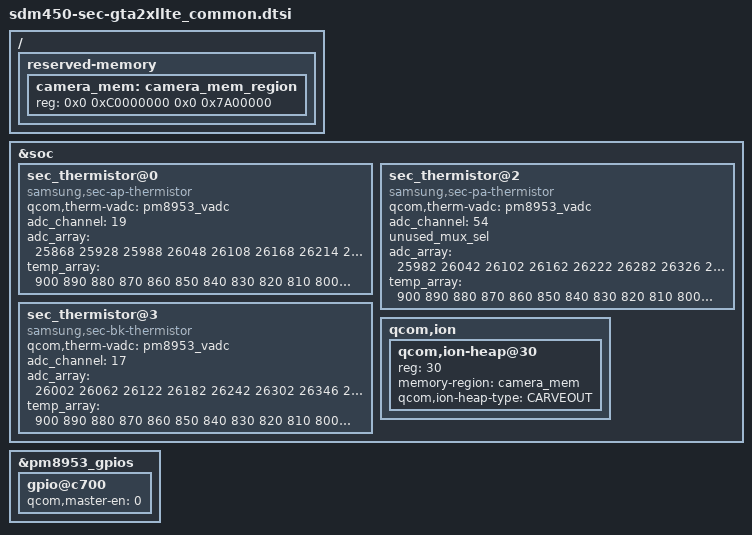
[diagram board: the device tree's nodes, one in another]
/* Copyright (c) 2017, The Linux Foundation. All rights reserved.
 *
 * This program is free software; you can redistribute it and/or modify
 * it under the terms of the GNU General Public License version 2 and
 * only version 2 as published by the Free Software Foundation.
 *
 * This program is distributed in the hope that it will be useful,
 * but WITHOUT ANY WARRANTY; without even the implied warranty of
 * MERCHANTABILITY or FITNESS FOR A PARTICULAR PURPOSE.  See the
 * GNU General Public License for more details.
 */

#include "../qcom/sdm450.dtsi"
#include "sdm450-sec-common.dtsi"
#include "sdm450-s2mu004.dtsi"
#include "sdm450-s2mm005.dtsi"
#include "sdm450-sec-gta2xllte_audio.dtsi"
#include "sdm450-sec-gta2xllte-input-common.dtsi"


/ {
	reserved-memory {
		camera_mem: camera_mem_region {
			reg = <0x0 0xC0000000 0x0 0x7A00000>;
		};
	};
};

&soc {
	/* Thermistor table */
	sec_thermistor@0 {
		compatible = "samsung,sec-ap-thermistor";
		qcom,therm-vadc = <&pm8953_vadc>;
		status = "okay";
		adc_channel = <19>;
					
		adc_array = <25868 25928 25988 26048 26108 26168 26214 26261 26307 26354
					26400 26447 26494 26540 26587 26634 26699 26765 26830 26896
					26961 27020 27080 27139 27199 27258 27352 27446 27539 27633
					27727 27842 27958 28073 28189 28304 28430 28556 28682 28808
					28934 29141 29349 29556 29764 29971 30163 30356 30548 30741
					30933 31122 31311 31499 31688 31877 32012 32147 32281 32416
					32551 32706 32861 33015 33170 33325 33593 33861 34129 34397
					34665 34889 35114 35338 35563 35787 35998 36209 36420 36631
					36842 37044 37245 37447 37648 37850 37994 38138 38283 38427
					38571 38743 38914 39086 39257 39429 39569 39709 39849 39989
					40129 40249 40370 40490 40611 40731 40826 40921 41015 41110
					41205>;

		temp_array = <900 890 880 870 860 850 840 830 820 810
			800 790 780 770 760 750 740 730 720 710
			700 690 680 670 660 650 640 630 620 610
			600 590 580 570 560 550 540 530 520 510
			500 490 480 470 460 450 440 430 420 410
			400 390 380 370 360 350 340 330 320 310
			300 290 280 270 260 250 240 230 220 210
			200 190 180 170 160 150 140 130 120 110
			100 90 80 70 60 50 40 30 20 10
			0 (-10) (-20) (-30) (-40) (-50) (-60) (-70) (-80) (-90)
			(-100) (-110) (-120) (-130) (-140) (-150) (-160) (-170) (-180) (-190)
			(-200)>;
	};
	
	/* PA Thermistor table */
	sec_thermistor@2 {
		compatible = "samsung,sec-pa-thermistor";
		qcom,therm-vadc = <&pm8953_vadc>;
		status = "okay";
		adc_channel = <54>;
		unused_mux_sel;

		adc_array = <25982 26042 26102 26162 26222 26282 26326 26369 26413 26456
					26500 26552 26604 26655 26707 26759 26827 26896 26964 27033
					27101 27162 27223 27284 27345 27406 27502 27599 27695 27792
					27888 28004 28120 28235 28351 28467 28598 28729 28860 28991
					29122 29292 29463 29633 29804 29974 30147 30321 30494 30668
					30841 31031 31222 31412 31603 31793 31991 32190 32388 32587
					32785 32985 33185 33384 33584 33784 34018 34252 34487 34721
					34955 35175 35395 35615 35835 36055 36271 36487 36704 36920
					37136 37338 37540 37742 37944 38146 38308 38470 38631 38793
					38955 39125 39295 39465 39635 39805 39945 40085 40226 40366
					40506 40626 40746 40866 40986 41106 41202 41297 41393 41488
					41584>;

		temp_array = <900 890 880 870 860 850 840 830 820 810
			800 790 780 770 760 750 740 730 720 710
			700 690 680 670 660 650 640 630 620 610
			600 590 580 570 560 550 540 530 520 510
			500 490 480 470 460 450 440 430 420 410
			400 390 380 370 360 350 340 330 320 310
			300 290 280 270 260 250 240 230 220 210
			200 190 180 170 160 150 140 130 120 110
			100 90 80 70 60 50 40 30 20 10
			0 (-10) (-20) (-30) (-40) (-50) (-60) (-70) (-80) (-90)
			(-100) (-110) (-120) (-130) (-140) (-150) (-160) (-170) (-180) (-190)
			(-200)>;
	};
	
	/* BLANKET Thermistor table */
	sec_thermistor@3 {
		compatible = "samsung,sec-bk-thermistor";
		qcom,therm-vadc = <&pm8953_vadc>;
		status = "okay";
		adc_channel = <17>;

		adc_array = <26002 26062 26122 26182 26242 26302 26346 26389 26433 26476
					26520 26571 26622 26673 26724 26775 26844 26913 26982 27051
					27120 27182 27244 27305 27367 27429 27525 27621 27718 27814
					27910 28024 28139 28253 28368 28482 28613 28743 28874 29004
					29135 29307 29479 29651 29823 29995 30167 30339 30511 30683
					30855 31045 31234 31424 31613 31803 32002 32201 32400 32599
					32798 33003 33208 33414 33619 33824 34049 34275 34500 34726
					34951 35168 35385 35601 35818 36035 36248 36462 36675 36889
					37102 37299 37496 37694 37891 38088 38246 38404 38563 38721
					38879 39042 39205 39369 39532 39695 39830 39965 40099 40234
					40369 40483 40597 40710 40824 40938 41028 41118 41207 41297
					41387>;

		temp_array = <900 890 880 870 860 850 840 830 820 810
			800 790 780 770 760 750 740 730 720 710
			700 690 680 670 660 650 640 630 620 610
			600 590 580 570 560 550 540 530 520 510
			500 490 480 470 460 450 440 430 420 410
			400 390 380 370 360 350 340 330 320 310
			300 290 280 270 260 250 240 230 220 210
			200 190 180 170 160 150 140 130 120 110
			100 90 80 70 60 50 40 30 20 10
			0 (-10) (-20) (-30) (-40) (-50) (-60) (-70) (-80) (-90)
			(-100) (-110) (-120) (-130) (-140) (-150) (-160) (-170) (-180) (-190)
			(-200)>;
	};

	qcom,ion {
		qcom,ion-heap@30 { /* CAMERA HEAP  */
			reg = <30>;
			memory-region = <&camera_mem>;
			qcom,ion-heap-type = "CARVEOUT";
		};
	};
};

&pm8953_gpios {
    /* GPIO 8 */
    gpio@c700 {
        qcom,master-en = <0>;
        status = "okay";
    };
};

